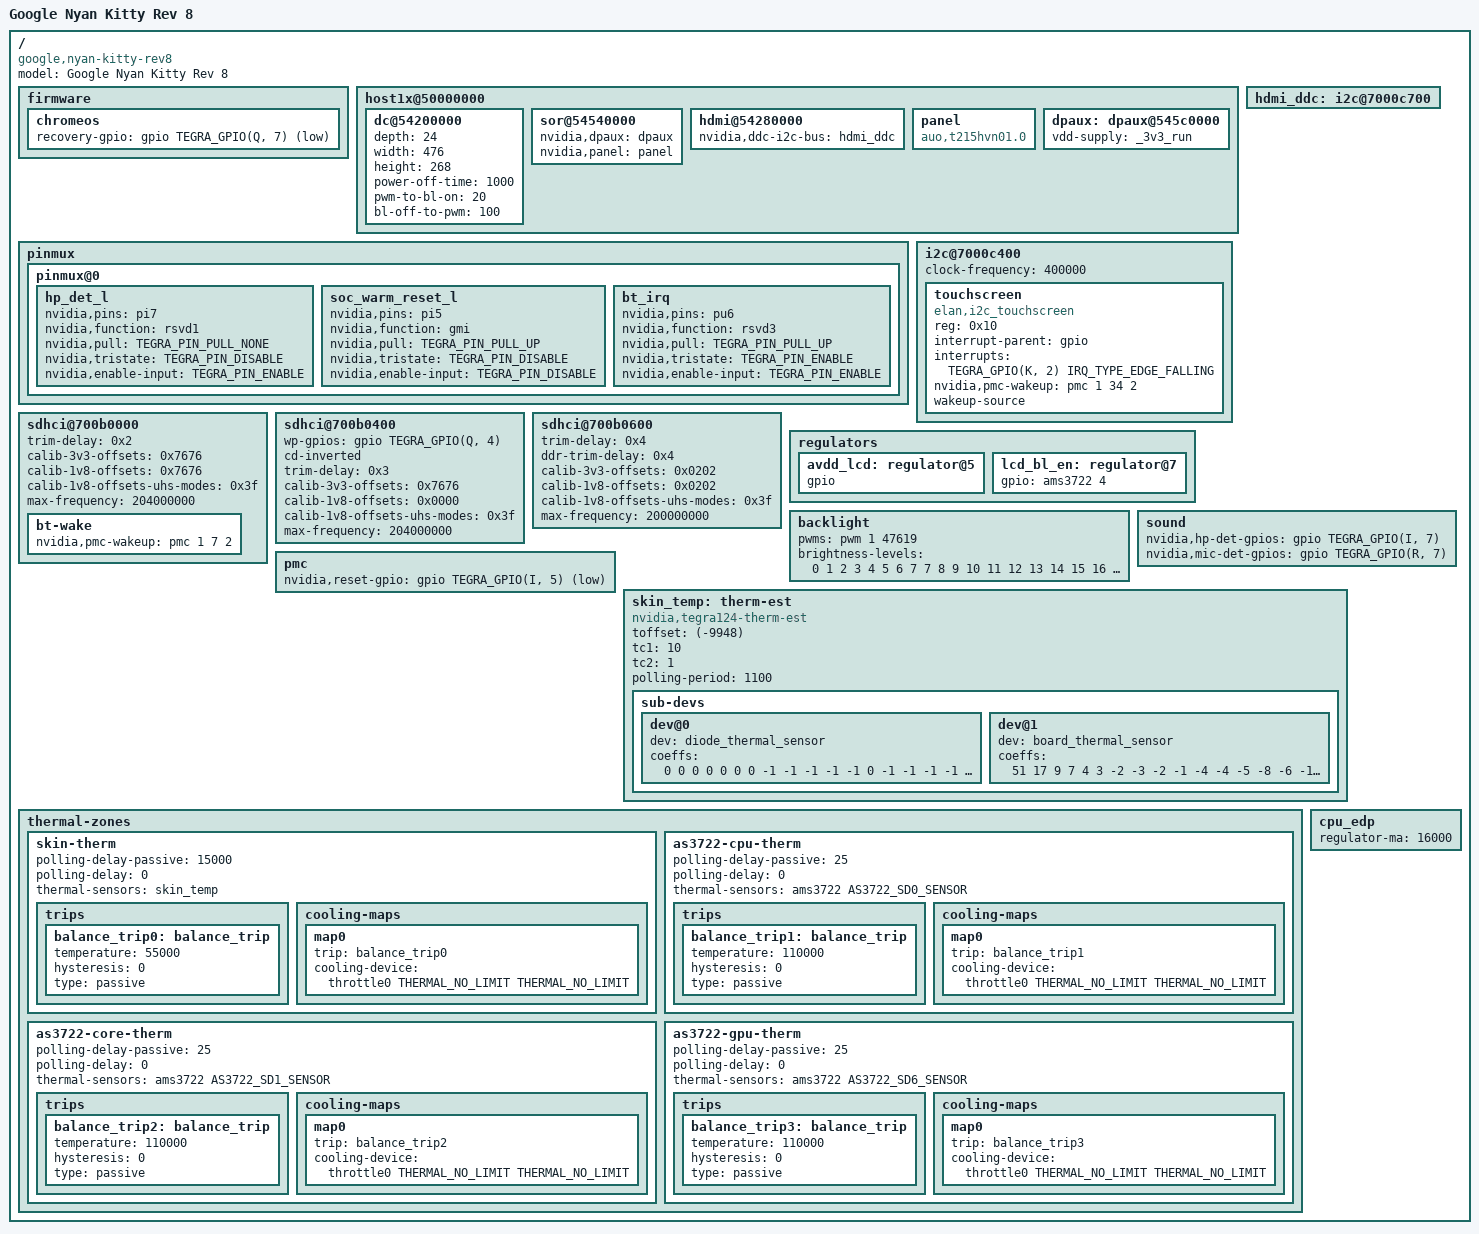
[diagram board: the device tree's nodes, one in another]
/dts-v1/;

#include "tegra124.dtsi"
#include "tegra124-nyan.dtsi"
#include "tegra124-nyan-kitty-emc.dtsi"

/ {
	model = "Google Nyan Kitty Rev 8";

	compatible = "google,nyan-kitty-rev8",
			"google,nyan", "nvidia,tegra124";

	firmware {
		chromeos {
			recovery-gpio = <&gpio TEGRA_GPIO(Q, 7) GPIO_ACTIVE_LOW>;
		};
	};

	host1x@50000000 {
		dc@54200000 {
			depth = <24>;
			width = <476>;
			height = <268>;
			power-off-time = <1000>;
			pwm-to-bl-on = <20>;
			bl-off-to-pwm = <100>;
		};

		sor@54540000 {
			status = "okay";

			nvidia,dpaux = <&dpaux>;
			nvidia,panel = <&panel>;
		};

		hdmi@54280000 {
			nvidia,ddc-i2c-bus = <&hdmi_ddc>;
		};

		panel: panel {
			compatible = "auo,t215hvn01.0", "simple-panel";
		};

		dpaux: dpaux@545c0000 {
			vdd-supply = <&_3v3_run>;
			status = "okay";
		};
	};

	hdmi_ddc: i2c@7000c700 {
		status = "okay";
	};

	pinmux {
		pinmux@0 {
			hp_det_l {
				nvidia,pins = "pi7";
				nvidia,function = "rsvd1";
				nvidia,pull = <TEGRA_PIN_PULL_NONE>;
				nvidia,tristate = <TEGRA_PIN_DISABLE>;
				nvidia,enable-input = <TEGRA_PIN_ENABLE>;
			};
			soc_warm_reset_l {
				nvidia,pins = "pi5";
				nvidia,function = "gmi";
				nvidia,pull = <TEGRA_PIN_PULL_UP>;
				nvidia,tristate = <TEGRA_PIN_DISABLE>;
				nvidia,enable-input = <TEGRA_PIN_DISABLE>;
			};
			bt_irq {
				nvidia,pins = "pu6";
				nvidia,function = "rsvd3";
				nvidia,pull = <TEGRA_PIN_PULL_UP>;
				nvidia,tristate = <TEGRA_PIN_ENABLE>;
				nvidia,enable-input = <TEGRA_PIN_ENABLE>;
			};
		};
	};

	i2c@7000c400 {
		clock-frequency = <400000>;
		touchscreen {
			compatible = "elan,i2c_touchscreen";
			reg = <0x10>;
			interrupt-parent = <&gpio>;
			interrupts = <TEGRA_GPIO(K, 2) IRQ_TYPE_EDGE_FALLING>;
			nvidia,pmc-wakeup = <&pmc 1 34 2>;
			wakeup-source;
		};
	};

	sdhci@700b0000 {
		trim-delay = <0x2>;
		calib-3v3-offsets = <0x7676>;
		calib-1v8-offsets = <0x7676>;
		calib-1v8-offsets-uhs-modes = <0x3f>;
		max-frequency = <204000000>;
		bt-wake {
			nvidia,pmc-wakeup = <&pmc 1 7 2>;
		};
	};

	sdhci@700b0400 {
		wp-gpios = <&gpio TEGRA_GPIO(Q, 4) GPIO_ACTIVE_HIGH>;
		cd-inverted;
		trim-delay = <0x3>;
		calib-3v3-offsets = <0x7676>;
		calib-1v8-offsets = <0x0000>;
		calib-1v8-offsets-uhs-modes = <0x3f>;
		max-frequency = <204000000>;
	};

	sdhci@700b0600 {
		trim-delay = <0x4>;
		ddr-trim-delay = <0x4>;
		calib-3v3-offsets = <0x0202>;
		calib-1v8-offsets = <0x0202>;
		calib-1v8-offsets-uhs-modes = <0x3f>;
		max-frequency = <200000000>;
	};

        regulators {
                avdd_lcd: regulator@5 {
                        gpio;
                };

                lcd_bl_en: regulator@7 {
                        gpio = <&ams3722 4 GPIO_ACTIVE_HIGH>; /* AS3722 GPIO 4 */
                };
        };

	backlight {
		pwms = <&pwm 1 47619>;
		brightness-levels =
			<  0   1   2   3   4   5   6   7
			   7   8   9  10  11  12  13  14
			  15  16  17  18  19  20  21  22
			  23  23  24  25  26  27  28  29
			  30  31  32  33  34  35  36  37
			  38  39  40  41  42  43  44  45
			  45  46  47  48  49  50  51  52
			  53  54  55  56  57  58  59  60
			  61  62  63  64  65  66  67  68
			  69  70  71  72  73  73  74  75
			  76  77  78  79  80  81  82  83
			  84  85  86  87  88  89  90  91
			  92  93  94  95  96  97  98  99
			 100 101 102 103 104 105 106 107
			 108 109 110 111 112 113 114 115
			 116 117 118 119 120 121 122 123
			 124 125 126 127 128 129 130 131
			 132 133 134 135 136 137 138 139
			 140 141 142 143 144 145 146 147
			 148 149 150 151 152 153 154 155
			 156 157 158 159 160 161 162 163
			 164 165 166 167 168 169 170 171
			 172 173 175 176 177 178 179 180
			 181 182 183 184 185 186 187 188
			 189 190 191 192 193 194 195 196
			 197 198 199 200 201 202 203 204
			 206 207 208 209 210 211 212 213
			 214 215 216 217 218 219 220 221
			 222 223 224 225 226 228 229 230
			 231 232 233 234 235 236 237 238
			 239 240 241 242 243 244 246 247
			 248 249 250 251 252 253 254 255
			 256>;
	};

	pmc {
		nvidia,reset-gpio = <&gpio TEGRA_GPIO(I, 5) GPIO_ACTIVE_LOW>;
	};

	sound {
		nvidia,hp-det-gpios = <&gpio TEGRA_GPIO(I, 7) GPIO_ACTIVE_HIGH>;
		nvidia,mic-det-gpios = <&gpio TEGRA_GPIO(R, 7)
							GPIO_ACTIVE_HIGH>;
	};

	skin_temp: therm-est {
		compatible = "nvidia,tegra124-therm-est";
		toffset = <(-9948)>;
		tc1 = <10>;
		tc2 = <1>;
		polling-period = <1100>;

		#thermal-sensor-cells = <0>;

		sub-devs {
			dev@0 {
				dev = <&diode_thermal_sensor>;
				coeffs = "0 0 0 0 0 0 0 -1 -1 -1 -1 -1 0 -1 -1 -1 -1 -1 -1 -4";
			};

			dev@1 {
				dev = <&board_thermal_sensor>;
				coeffs = "51 17 9 7 4 3 -2 -3 -2 -1 -4 -4 -5 -8 -6 -1 -1 0 11 57";
			};
		};
	};

	thermal-zones {
		skin-therm {
			polling-delay-passive = <15000>; /* milliseconds */
			polling-delay = <0>; /* milliseconds */

			thermal-sensors = <&skin_temp>;

			trips {
				balance_trip0: balance_trip {
					temperature = <55000>; /* millicelsius */
					hysteresis = <0>; /* millicelsius */
					type = "passive";
				};
			};

			cooling-maps {
				map0 {
					trip = <&balance_trip0>;
					cooling-device = <&throttle0 THERMAL_NO_LIMIT THERMAL_NO_LIMIT>;
				};
			};
		};
		as3722-cpu-therm {
			polling-delay-passive = <25>; /* milliseconds */
			polling-delay = <0>; /* milliseconds */
			thermal-sensors = <&ams3722 AS3722_SD0_SENSOR>;

			trips {
				balance_trip1: balance_trip {
					temperature = <110000>; /* millicelsius */
					hysteresis = <0>; /* millicelsius */
					type = "passive";
				};
			};

			cooling-maps {
				map0 {
					trip = <&balance_trip1>;
					cooling-device = <&throttle0 THERMAL_NO_LIMIT THERMAL_NO_LIMIT>;
				};
			};
		};
		as3722-core-therm {
			polling-delay-passive = <25>; /* milliseconds */
			polling-delay = <0>; /* milliseconds */
			thermal-sensors = <&ams3722 AS3722_SD1_SENSOR>;

			trips {
				balance_trip2: balance_trip {
					temperature = <110000>; /* millicelsius */
					hysteresis = <0>; /* millicelsius */
					type = "passive";
				};
			};

			cooling-maps {
				map0 {
					trip = <&balance_trip2>;
					cooling-device = <&throttle0 THERMAL_NO_LIMIT THERMAL_NO_LIMIT>;
				};
			};
		};
		as3722-gpu-therm {
			polling-delay-passive = <25>; /* milliseconds */
			polling-delay = <0>; /* milliseconds */
			thermal-sensors = <&ams3722 AS3722_SD6_SENSOR>;

			trips {
				balance_trip3: balance_trip {
					temperature = <110000>; /* millicelsius */
					hysteresis = <0>; /* millicelsius */
					type = "passive";
				};
			};

			cooling-maps {
				map0 {
					trip = <&balance_trip3>;
					cooling-device = <&throttle0 THERMAL_NO_LIMIT THERMAL_NO_LIMIT>;
				};
			};
		};
	};

	cpu_edp {
		regulator-ma = <16000>;
	};
};
